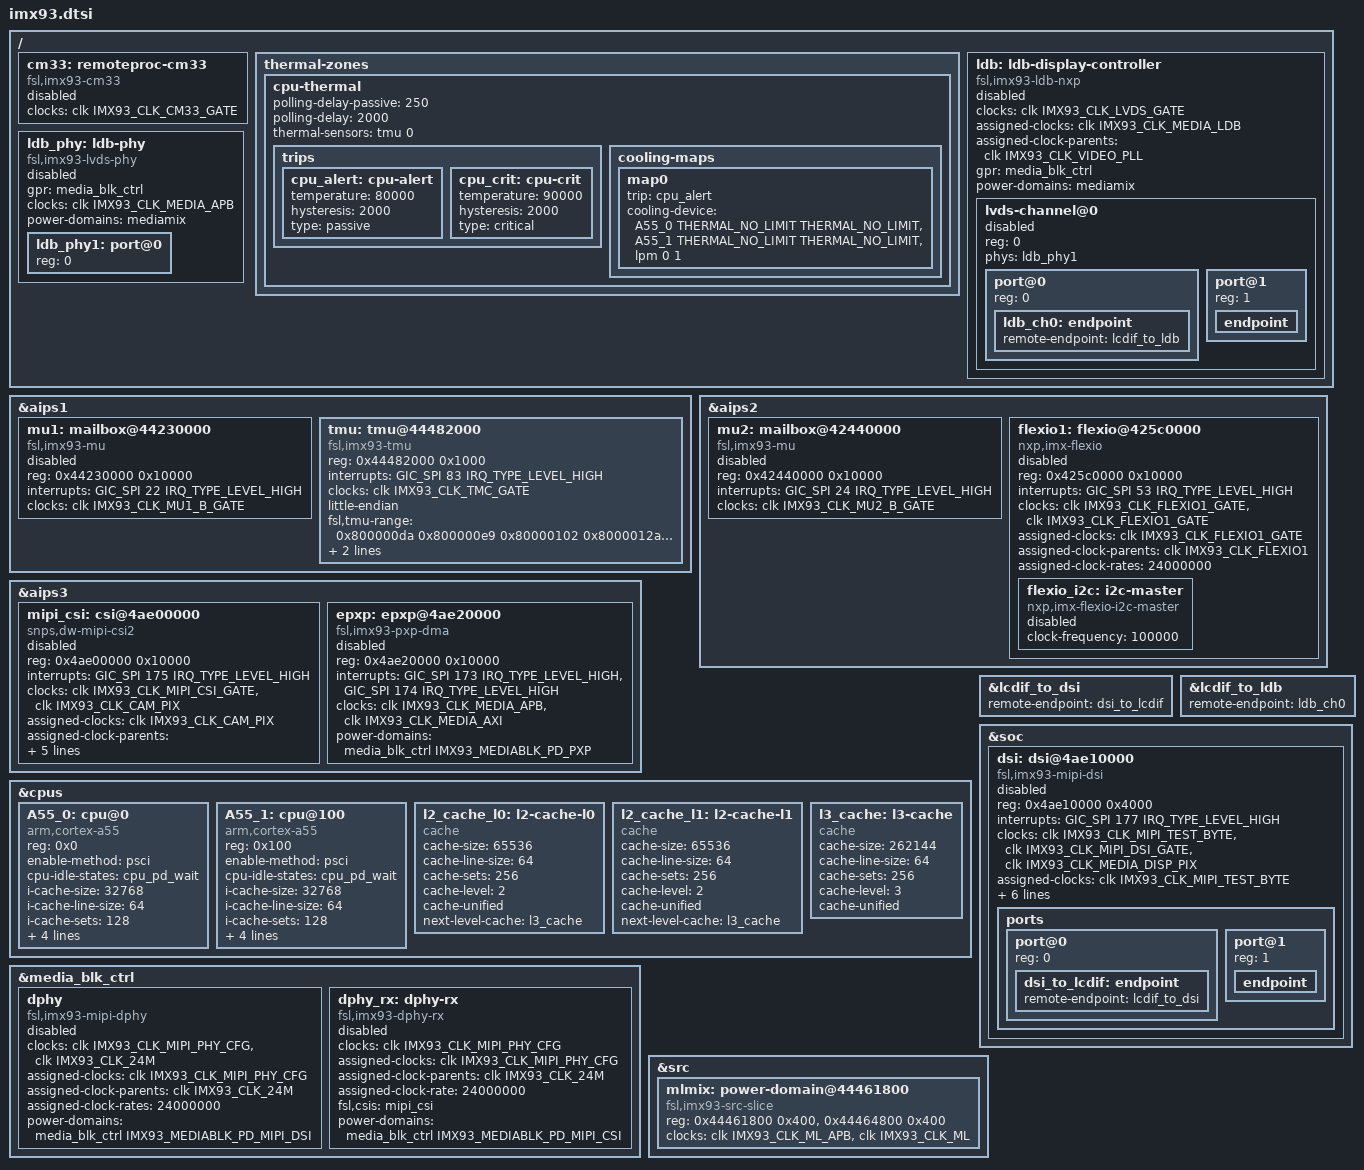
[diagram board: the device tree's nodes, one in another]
// SPDX-License-Identifier: (GPL-2.0+ OR MIT)
/*
 * Copyright 2022,2025 NXP
 */

#include "imx91_93_common.dtsi"

/{
	cm33: remoteproc-cm33 {
		compatible = "fsl,imx93-cm33";
		clocks = <&clk IMX93_CLK_CM33_GATE>;
		status = "disabled";
	};

	thermal-zones {
		cpu-thermal {
			polling-delay-passive = <250>;
			polling-delay = <2000>;

			thermal-sensors = <&tmu 0>;

			trips {
				cpu_alert: cpu-alert {
					temperature = <80000>;
					hysteresis = <2000>;
					type = "passive";
				};

				cpu_crit: cpu-crit {
					temperature = <90000>;
					hysteresis = <2000>;
					type = "critical";
				};
			};

			cooling-maps {
				map0 {
					trip = <&cpu_alert>;
					cooling-device =
						<&A55_0 THERMAL_NO_LIMIT THERMAL_NO_LIMIT>,
						<&A55_1 THERMAL_NO_LIMIT THERMAL_NO_LIMIT>,
						<&lpm 0 1>;
				};
			};
		};
	};

	ldb: ldb-display-controller {
		#address-cells = <1>;
		#size-cells = <0>;
		compatible = "fsl,imx93-ldb-nxp";
		clocks = <&clk IMX93_CLK_LVDS_GATE>;
		clock-names = "ldb";
		assigned-clocks = <&clk IMX93_CLK_MEDIA_LDB>;
		assigned-clock-parents = <&clk IMX93_CLK_VIDEO_PLL>;
		gpr = <&media_blk_ctrl>;
		power-domains = <&mediamix>;
		status = "disabled";

		lvds-channel@0 {
			#address-cells = <1>;
			#size-cells = <0>;
			reg = <0>;
			phys = <&ldb_phy1>;
			phy-names = "ldb_phy";
			status = "disabled";

			port@0 {
				reg = <0>;

				ldb_ch0: endpoint {
					remote-endpoint = <&lcdif_to_ldb>;
				};
			};

			port@1 {
				reg = <1>;
				endpoint {
				};
			};
		};
	};

	ldb_phy: ldb-phy {
		compatible = "fsl,imx93-lvds-phy";
		#address-cells = <1>;
		#size-cells = <0>;
		gpr = <&media_blk_ctrl>;
		clocks = <&clk IMX93_CLK_MEDIA_APB>;
		clock-names = "apb";
		power-domains = <&mediamix>;
		status = "disabled";

		ldb_phy1: port@0 {
			reg = <0>;
			#phy-cells = <0>;
		};
	};
};

&aips1 {
	mu1: mailbox@44230000 {
		compatible = "fsl,imx93-mu", "fsl,imx8ulp-mu";
		reg = <0x44230000 0x10000>;
		interrupts = <GIC_SPI 22 IRQ_TYPE_LEVEL_HIGH>;
		clocks = <&clk IMX93_CLK_MU1_B_GATE>;
		#mbox-cells = <2>;
		status = "disabled";
	};

	tmu: tmu@44482000 {
		compatible ="fsl,imx93-tmu", "fsl,qoriq-tmu";
		reg = <0x44482000 0x1000>;
		interrupts = <GIC_SPI 83 IRQ_TYPE_LEVEL_HIGH>;
		clocks = <&clk IMX93_CLK_TMC_GATE>;
		#thermal-sensor-cells = <1>;
		little-endian;
		fsl,tmu-range = <0x800000da 0x800000e9
				 0x80000102 0x8000012a
				 0x80000166 0x800001a7
				 0x800001b6>;
		fsl,tmu-calibration = <0x00000000 0x0000000e
				       0x00000001 0x00000029
				       0x00000002 0x00000056
				       0x00000003 0x000000a2
				       0x00000004 0x00000116
				       0x00000005 0x00000195
				       0x00000006 0x000001b2>;
	};
};

&aips2 {
	mu2: mailbox@42440000 {
		compatible = "fsl,imx93-mu", "fsl,imx8ulp-mu";
		reg = <0x42440000 0x10000>;
		interrupts = <GIC_SPI 24 IRQ_TYPE_LEVEL_HIGH>;
		clocks = <&clk IMX93_CLK_MU2_B_GATE>;
		#mbox-cells = <2>;
		status = "disabled";
	};

	flexio1: flexio@425c0000 {
		compatible = "nxp,imx-flexio";
		reg = <0x425c0000 0x10000>;
		interrupts = <GIC_SPI 53 IRQ_TYPE_LEVEL_HIGH>;
		clocks = <&clk IMX93_CLK_FLEXIO1_GATE>,
			 <&clk IMX93_CLK_FLEXIO1_GATE>;
		clock-names = "per", "ipg";
		assigned-clocks = <&clk IMX93_CLK_FLEXIO1_GATE>;
		assigned-clock-parents = <&clk IMX93_CLK_FLEXIO1>;
		assigned-clock-rates = <24000000>;
		status = "disabled";

		flexio_i2c: i2c-master {
			#address-cells = <1>;
			#size-cells = <0>;
			compatible = "nxp,imx-flexio-i2c-master";
			clock-frequency = <100000>;
			status = "disabled";
		};
	};
};

&aips3 {
	mipi_csi: csi@4ae00000 {
		compatible = "snps,dw-mipi-csi2", "syscon";
		reg = <0x4ae00000 0x10000>;
		interrupts = <GIC_SPI 175 IRQ_TYPE_LEVEL_HIGH>;
		clocks = <&clk IMX93_CLK_MIPI_CSI_GATE>,
			 <&clk IMX93_CLK_CAM_PIX>;
		clock-names = "per", "pixel";
		assigned-clocks = <&clk IMX93_CLK_CAM_PIX>;
		assigned-clock-parents = <&clk IMX93_CLK_SYS_PLL_PFD0>;
		assigned-clock-rates = <140000000>;
		phys = <&dphy_rx>;
		phy-names = "dphy-rx";
		power-domains = <&media_blk_ctrl IMX93_MEDIABLK_PD_MIPI_CSI>;
		status = "disabled";
	};

	epxp: epxp@4ae20000 {
		compatible = "fsl,imx93-pxp-dma", "fsl,imx8ulp-pxp-dma";
		reg = <0x4ae20000 0x10000>;
		interrupts = <GIC_SPI 173 IRQ_TYPE_LEVEL_HIGH>,
			     <GIC_SPI 174 IRQ_TYPE_LEVEL_HIGH>;
		clocks = <&clk IMX93_CLK_MEDIA_APB>,
			 <&clk IMX93_CLK_MEDIA_AXI>;
		clock-names = "pxp_ipg", "pxp_axi";
		power-domains = <&media_blk_ctrl IMX93_MEDIABLK_PD_PXP>;
		status = "disabled";
	};
};

&cpus {
	A55_0: cpu@0 {
		device_type = "cpu";
		compatible = "arm,cortex-a55";
		reg = <0x0>;
		enable-method = "psci";
		#cooling-cells = <2>;
		cpu-idle-states = <&cpu_pd_wait>;
		i-cache-size = <32768>;
		i-cache-line-size = <64>;
		i-cache-sets = <128>;
		d-cache-size = <32768>;
		d-cache-line-size = <64>;
		d-cache-sets = <128>;
		next-level-cache = <&l2_cache_l0>;
	};

	A55_1: cpu@100 {
		device_type = "cpu";
		compatible = "arm,cortex-a55";
		reg = <0x100>;
		enable-method = "psci";
		#cooling-cells = <2>;
		cpu-idle-states = <&cpu_pd_wait>;
		i-cache-size = <32768>;
		i-cache-line-size = <64>;
		i-cache-sets = <128>;
		d-cache-size = <32768>;
		d-cache-line-size = <64>;
		d-cache-sets = <128>;
		next-level-cache = <&l2_cache_l1>;
	};

	l2_cache_l0: l2-cache-l0 {
		compatible = "cache";
		cache-size = <65536>;
		cache-line-size = <64>;
		cache-sets = <256>;
		cache-level = <2>;
		cache-unified;
		next-level-cache = <&l3_cache>;
	};

	l2_cache_l1: l2-cache-l1 {
		compatible = "cache";
		cache-size = <65536>;
		cache-line-size = <64>;
		cache-sets = <256>;
		cache-level = <2>;
		cache-unified;
		next-level-cache = <&l3_cache>;
	};

	l3_cache: l3-cache {
		compatible = "cache";
		cache-size = <262144>;
		cache-line-size = <64>;
		cache-sets = <256>;
		cache-level = <3>;
		cache-unified;
	};
};

&lcdif_to_dsi {
	remote-endpoint = <&dsi_to_lcdif>;
};

&lcdif_to_ldb {
	remote-endpoint = <&ldb_ch0>;
};

&media_blk_ctrl {
	dphy: dphy {
		compatible = "fsl,imx93-mipi-dphy";
		clocks = <&clk IMX93_CLK_MIPI_PHY_CFG>,
			 <&clk IMX93_CLK_24M>;
		clock-names = "phy_cfg", "phy_ref";
		assigned-clocks = <&clk IMX93_CLK_MIPI_PHY_CFG>;
		assigned-clock-parents = <&clk IMX93_CLK_24M>;
		assigned-clock-rates = <24000000>;
		#phy-cells = <0>;
		power-domains = <&media_blk_ctrl IMX93_MEDIABLK_PD_MIPI_DSI>;
		status = "disabled";
	};

	dphy_rx: dphy-rx {
		compatible = "fsl,imx93-dphy-rx";
		clocks = <&clk IMX93_CLK_MIPI_PHY_CFG>;
		clock-names = "phy_cfg";
		assigned-clocks = <&clk IMX93_CLK_MIPI_PHY_CFG>;
		assigned-clock-parents = <&clk IMX93_CLK_24M>;
		assigned-clock-rate = <24000000>;
		#phy-cells = <0>;
		fsl,csis = <&mipi_csi>;
		power-domains = <&media_blk_ctrl IMX93_MEDIABLK_PD_MIPI_CSI>;
		status = "disabled";
	};
};

&soc {
	dsi: dsi@4ae10000 {
		compatible = "fsl,imx93-mipi-dsi";
		reg = <0x4ae10000 0x4000>;
		interrupts = <GIC_SPI 177 IRQ_TYPE_LEVEL_HIGH>;
		clocks = <&clk IMX93_CLK_MIPI_TEST_BYTE>,
			 <&clk IMX93_CLK_MIPI_DSI_GATE>,
			 <&clk IMX93_CLK_MEDIA_DISP_PIX>;
		clock-names = "byte", "pclk", "pixel";
		assigned-clocks = <&clk IMX93_CLK_MIPI_TEST_BYTE>;
		assigned-clock-parents = <&clk IMX93_CLK_SYS_PLL_PFD0>;
		assigned-clock-rates = <20000000>;
		phys = <&dphy>;
		phy-names = "dphy";
		power-domains = <&media_blk_ctrl IMX93_MEDIABLK_PD_MIPI_DSI>;
		status = "disabled";

		ports {
			#address-cells = <1>;
			#size-cells = <0>;

			port@0 {
				reg = <0>;

				dsi_to_lcdif: endpoint {
					remote-endpoint = <&lcdif_to_dsi>;
				};
			};

			port@1 {
				reg = <1>;
				endpoint {
				};
			};
		};
	};
};

&src {
	mlmix: power-domain@44461800 {
		compatible = "fsl,imx93-src-slice";
		reg = <0x44461800 0x400>, <0x44464800 0x400>;
		clocks = <&clk IMX93_CLK_ML_APB>,
			 <&clk IMX93_CLK_ML>;
		#power-domain-cells = <0>;
	};
};
